# Air001xx_DFP register map
Vendor: AirM2M; Series: Air001; File version: 1.0.0
CPU: CM0+ r0p1, little endian, no MPU, no FPU, 4 interrupt priority bits
Registers are 32-bit, read-write, reset 0x0 unless marked. A register's access mark holds for its fields unless they carry their own. Offsets are from the block's base; [hi:lo] are bit positions; {n}, {i} and the like mark numbered series.

## FLASH
Base 0x40022000
0x00 ACR reset 0x600 — Access control register
  [0] LATENCY
0x08 KEYR wo — Flash key register
  [31:0] KEY — Flash key
0x0C OPTKEYR wo — Option byte key register
  [31:0] OPTKEY — Option byte key
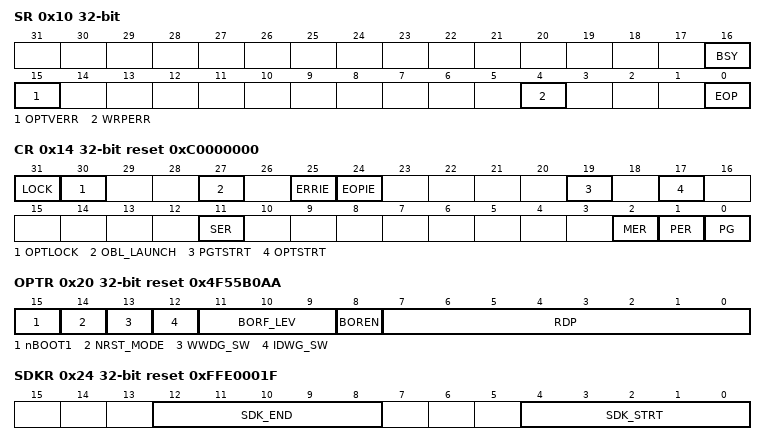
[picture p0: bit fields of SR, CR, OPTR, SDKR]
0x10 SR — Status register
  [16] BSY — Busy
  [15] OPTVERR — Option and Engineering bits loading validity error
  [4] WRPERR — Write protected error
  [0] EOP — End of operation
0x14 CR reset 0xC0000000 — Flash control register
  [31] LOCK — FLASH_CR Lock
  [30] OPTLOCK — Options Lock
  [27] OBL_LAUNCH — Force the option byte loading
  [25] ERRIE — Error interrupt enable
  [24] EOPIE — End of operation interrupt enable
  [19] PGTSTRT — Flash main memory program start
  [17] OPTSTRT — Option byte program start
  [11] SER — Sector erase
  [2] MER — Mass erase
  [1] PER — Page erase
  [0] PG — Programming
0x20 OPTR reset 0x4F55B0AA — Flash option register
  [15] nBOOT1 — Boot configuration
  [14] NRST_MODE
  [13] WWDG_SW — Window watchdog selection
  [12] IDWG_SW — Independent watchdog selection
  [11:9] BORF_LEV — These bits contain the VDD supply level threshold that activates the reset
  [8] BOREN — BOR reset Level
  [7:0] RDP — Read Protection
0x24 SDKR reset 0xFFE0001F — Flash SDK address register
  [12:8] SDK_END — SDK area end address
  [4:0] SDK_STRT — SDK area start address
0x2C WRPR reset 0xFFFF — Flash WRP address register
  [15:0] WRP — WRP address
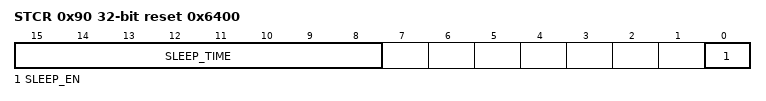
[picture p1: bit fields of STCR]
0x90 STCR reset 0x6400 — Flash sleep time config register
  [15:8] SLEEP_TIME — FLash sleep time configuration(counter based on HSI_10M)
  [0] SLEEP_EN — FLash sleep enable
0x100 TS0 reset 0xB4 — Flash TS0 register
  [7:0] TS0 — FLash TS0 register
0x104 TS1 reset 0x1B0 — Flash TS1 register
  [8:0] TS1 — FLash TS1 register
0x108 TS2P reset 0xB4 — Flash TS2P register
  [7:0] TS2P — FLash TS2P register
0x10C TPS3 reset 0x6C0 — Flash TPS3 register
  [10:0] TPS3 — FLash TPS3 register
0x110 TS3 reset 0xB4 — Flash TS3 register
  [7:0] TS3 — FLash TS3 register
0x114 PERTPE reset 0xEA60 — Flash PERTPE register
  [16:0] PERTPE — FLash PERTPE register
0x118 SMERTPE reset 0xFD20 — Flash SMERTPE register
  [16:0] SMERTPE — FLash SMERTPE register
0x11C PRGTPE reset 0x8CA0 — Flash PRGTPE register
  [15:0] PRGTPE — FLash PRGTPE register
0x120 PRETPE reset 0x12C0 — Flash PRETPE register
  [12:0] PRETPE — FLash PRETPE register

## CRC — CRC calculation unit
Base 0x40023000
0x00 DR reset 0xFFFFFFFF — Data register
  [31:0] DR — Data Register
0x04 IDR — Independent Data register
  [7:0] IDR
0x08 CR wo — Control register
  [0] RESET — Reset bit

## SPI1 — Serial peripheral interface
Base 0x40013000
Same registers: SPI2 0x40003800
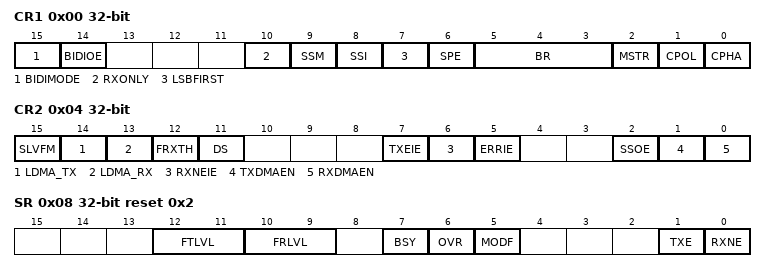
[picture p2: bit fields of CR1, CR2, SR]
0x00 CR1 — control register 1
  [15] BIDIMODE — Bidirectional data mode enable
  [14] BIDIOE — Output enable in bidirectional mode
  [10] RXONLY — Receive only
  [9] SSM — Software slave management
  [8] SSI — Internal slave selection
  [7] LSBFIRST — Frame format
  [6] SPE — SPI enable
  [5:3] BR — Baud rate control
  [2] MSTR — Master selection
  [1] CPOL — Clock polarity
  [0] CPHA — Clock phase
0x04 CR2 — control register 2
  [15] SLVFM — Slave fast mode enable
  [14] LDMA_TX — Last DAM Transmit(TX)
  [13] LDMA_RX — Last DAM Transmit(RX)
  [12] FRXTH — FIFO reception threshold
  [11] DS — Data length
  [7] TXEIE — Tx buffer empty interrupt enable
  [6] RXNEIE — RX buffer not empty interrupt enable
  [5] ERRIE — Error interrupt enable
  [2] SSOE — SS output enable
  [1] TXDMAEN — Tx buffer DMA enable
  [0] RXDMAEN — Rx buffer DMA enable
0x08 SR reset 0x2 — status register
  [12:11] FTLVL ro — FIFO transmission level
  [10:9] FRLVL ro — FIFO reception level
  [7] BSY ro — Busy flag
  [6] OVR ro — Overrun flag
  [5] MODF ro — Mode fault
  [1] TXE ro — Transmit buffer empty
  [0] RXNE ro — Receive buffer not empty
0x0C DR — data register
  [15:0] DR — Data register

## I2C — Inter integrated circuit
Base 0x40005400
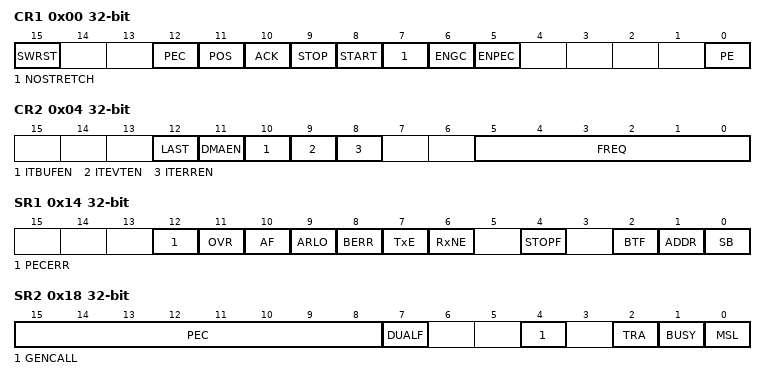
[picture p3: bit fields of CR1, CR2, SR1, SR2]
0x00 CR1 — Control register 1
  [15] SWRST — Software reset
  [12] PEC — Packet error checking
  [11] POS — Acknowledge/PEC Position (for data reception)
  [10] ACK — Acknowledge enable
  [9] STOP — Stop generation
  [8] START — Start generation
  [7] NOSTRETCH — Clock stretching disable (Slave mode)
  [6] ENGC — General call enable
  [5] ENPEC — PEC enable
  [0] PE — Peripheral enable
0x04 CR2 — Control register 2
  [12] LAST — DMA last transfer
  [11] DMAEN — DMA requests enable
  [10] ITBUFEN — Buffer interrupt enable
  [9] ITEVTEN — Event interrupt enable
  [8] ITERREN — Error interrupt enable
  [5:0] FREQ — Peripheral clock frequency
0x08 OAR1 — Own address register 1
  [7:1] ADD — Interface address
0x10 DR — Data register
  [7:0] DR — 8-bit data register
0x14 SR1 — Status register 1
  [12] PECERR — PEC Error in reception
  [11] OVR — Overrun/Underrun
  [10] AF — Acknowledge failure
  [9] ARLO — Arbitration lost (master mode)
  [8] BERR — Bus error
  [7] TxE ro — Data register empty (transmitters)
  [6] RxNE ro — Data register not empty (receivers)
  [4] STOPF ro — Stop detection (slave mode)
  [2] BTF ro — Byte transfer finished
  [1] ADDR ro — Address sent (master mode)/matched (slave mode)
  [0] SB ro — Start bit (Master mode)
0x18 SR2 ro — Status register 2
  [15:8] PEC — acket error checking register
  [7] DUALF — Dual flag (Slave mode)
  [4] GENCALL — General call address (Slave mode)
  [2] TRA — Transmitter/receiver
  [1] BUSY — Bus busy
  [0] MSL — Master/slave
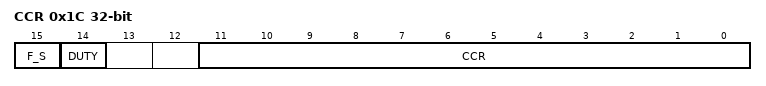
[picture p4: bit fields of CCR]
0x1C CCR — Clock control register
  [15] F_S — I2C master mode selection
  [14] DUTY — Fast mode duty cycle
  [11:0] CCR — Clock control register in Fast/Standard mode (Master mode)
0x20 TRISE reset 0x2
  [5:0] TRISE — Maximum rise time in Fast/Standard mode (Master mode)

## LED — LED CONTROLLER
Base 0x40002400
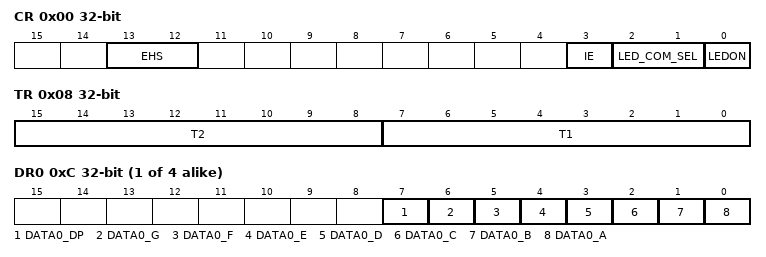
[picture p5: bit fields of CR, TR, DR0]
0x00 CR — Control register
  [13:12] EHS — Light control
  [3] IE — LED interrupt enable
  [2:1] LED_COM_SEL — LED COM Selection
  [0] LEDON — LED enable
0x04 PR — Prescaler register
  [7:0] PR — Prescaler control
0x08 TR — Time register
  [15:8] T2 — Switch time
  [7:0] T1 — Light on time
{0xC+4i} DR{i} (i=0..3) — Data{i} register
  [7] DATA{i}_DP — 8-bit data register
  [6] DATA{i}_G — 8-bit data register
  [5] DATA{i}_F — 8-bit data register
  [4] DATA{i}_E — 8-bit data register
  [3] DATA{i}_D — 8-bit data register
  [2] DATA{i}_C — 8-bit data register
  [1] DATA{i}_B — 8-bit data register
  [0] DATA{i}_A — 8-bit data register
0x1C IR — Interrupt register 1
  [0] FLAG — interrupt flag

## DBGMCU — Debug support
Base 0x40015800
0x00 IDCODE ro — MCU Device ID Code Register
0x04 CR — Debug MCU Configuration Register
  [1] DBG_STOP — Debug Stop Mode
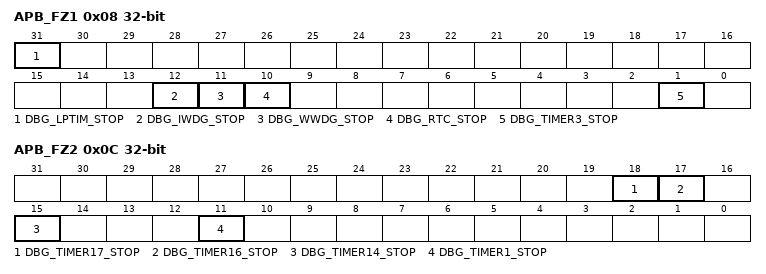
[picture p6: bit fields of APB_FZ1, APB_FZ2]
0x08 APB_FZ1 — APB Freeze Register1
  [31] DBG_LPTIM_STOP — Debug LPTIM stopped when Core is halted
  [12] DBG_IWDG_STOP — Debug Independent Wachdog stopped when Core is halted
  [11] DBG_WWDG_STOP — Debug Window Wachdog stopped when Core is halted
  [10] DBG_RTC_STOP — Debug RTC stopped when Core is halted
  [1] DBG_TIMER3_STOP — Debug Timer 3 stopped when Core is halted
0x0C APB_FZ2 — APB Freeze Register2
  [18] DBG_TIMER17_STOP — Debug Timer 17 stopped when Core is halted
  [17] DBG_TIMER16_STOP — Debug Timer 16 stopped when Core is halted
  [15] DBG_TIMER14_STOP — Debug Timer 14 stopped when Core is halted
  [11] DBG_TIMER1_STOP — Debug Timer 1 stopped when Core is halted
